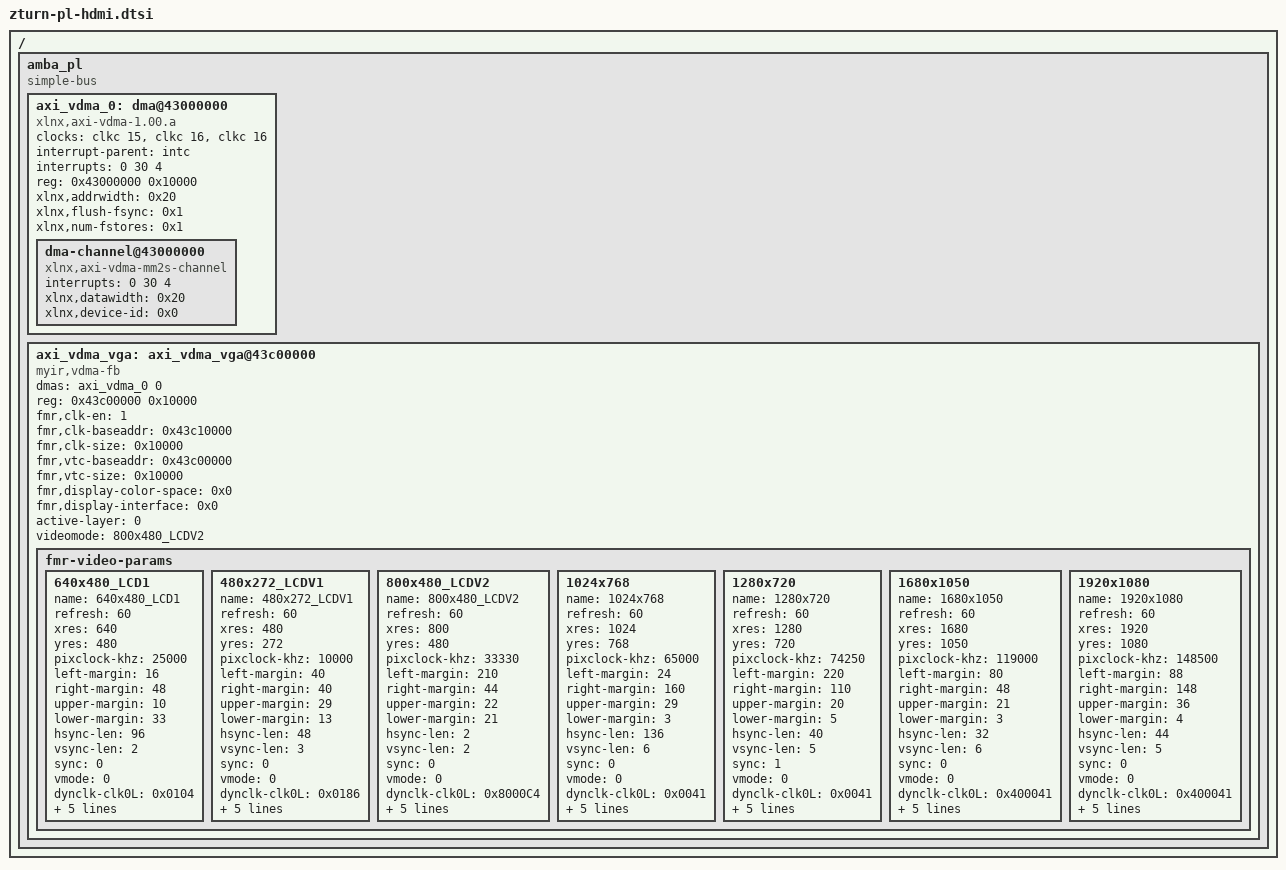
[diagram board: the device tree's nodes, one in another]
/*
 * CAUTION: This file is automatically generated by Xilinx.
 * Version:  
 * Today is: Tue Dec 25 14:02:03 2018
 */


/ {
	amba_pl: amba_pl {
		#address-cells = <1>;
		#size-cells = <1>;
		compatible = "simple-bus";
		ranges ;

		axi_vdma_0: dma@43000000 {
			#dma-cells = <1>;
			clock-names = "s_axi_lite_aclk", "m_axi_mm2s_aclk", "m_axi_mm2s_aclk";
			clocks = <&clkc 15>, <&clkc 16>, <&clkc 16>;
			compatible = "xlnx,axi-vdma-1.00.a";
			interrupt-names = "mm2s_introut";
			interrupt-parent = <&intc>;
			interrupts = <0 30 4>;
			reg = <0x43000000 0x10000>;
			xlnx,addrwidth = <0x20>;
			xlnx,flush-fsync = <0x1>;
			xlnx,num-fstores = <0x1>;
			dma-channel@43000000 {
				compatible = "xlnx,axi-vdma-mm2s-channel";
				interrupts = <0 30 4>;
				xlnx,datawidth = <0x20>;
				xlnx,device-id = <0x0>;
			};
		};

		axi_vdma_vga: axi_vdma_vga@43c00000 {
			compatible = "myir,vdma-fb";
			dmas = <&axi_vdma_0 0>;
			dma-names = "axivdma";
			reg = <0x43c00000 0x10000>;
			fmr,clk-en = <1>; // enable or disable dynclk
			fmr,clk-baseaddr = <0x43c10000>;
			fmr,clk-size = <0x10000>;
			fmr,vtc-baseaddr = <0x43c00000>; 
			fmr,vtc-size = <0x10000>; 
			fmr,display-color-space = <0x0>; 	//RGB
			fmr,display-interface = <0x0>;
			active-layer = <0>;
			videomode = "800x480_LCDV2";

			fmr-video-params {
				640x480_LCD1{
					name = "640x480_LCD1";
					refresh = <60>;
					xres = <640>;
					yres = <480>;
					pixclock-khz = <25000>;
					left-margin = <16>;
					right-margin = <48>;
					upper-margin = <10>;
					lower-margin = <33>;
					hsync-len = <96>;
					vsync-len = <2>;
					sync = <0>;
					vmode = <0>;

					dynclk-clk0L = <0x0104>;
					dynclk-clkFBL = <0x0145>;
					dynclk-clkFBH_clk0H = <0>;
					dynclk-divclk = <0x1041>;
					dynclk-lockL = <0x3E8FA401>;
					dynclk-fltr_lockH = <0x4B00E7>;
				};
				480x272_LCDV1{
					name = "480x272_LCDV1";
					refresh = <60>;
					xres = <480>;
					yres = <272>;
					pixclock-khz = <10000>;
					left-margin = <40>;
					right-margin = <40>;
					upper-margin = <29>;
					lower-margin = <13>;
					hsync-len = <48>;
					vsync-len = <3>;
					sync = <0>;
					vmode = <0>;

					dynclk-clk0L = <0x0186>;
					dynclk-clkFBL = <0x00C3>;
					dynclk-clkFBH_clk0H = <0>;
					dynclk-divclk = <0x1041>;
					dynclk-lockL = <0x7E8FA401>;
					dynclk-fltr_lockH = <0x73008C>;
				};
				800x480_LCDV2 {
					name = "800x480_LCDV2";
					refresh = <60>;
					xres = <800>;
					yres = <480>;
					pixclock-khz = <33330>;
					left-margin = <210>;
					right-margin = <44>;
					upper-margin = <22>;
					lower-margin = <21>;
					hsync-len = <2>;
					vsync-len = <2>;
					sync = <0>;
					vmode = <0>;

					dynclk-clk0L = <0x8000C4>;
					dynclk-clkFBL = <0x800452>;
					dynclk-clkFBH_clk0H = <0>;
					dynclk-divclk = <0x2042>;
					dynclk-lockL = <0xD13FA401>;
					dynclk-fltr_lockH = <0x6300FF>;
				};
				1024x768 {
					name = "1024x768";
					refresh = <60>;
					xres = <1024>;
					yres = <768>;
					pixclock-khz = <65000>;
					left-margin = <24>;//H Front Porch
					right-margin = <160>;//H Back Porch
					upper-margin = <29>;//V Back Porch
					lower-margin = <3>;//V Front Porch
					hsync-len = <136>;//H Sync Time
					vsync-len = <6>;//V Sync Time
					sync = <0>;
					vmode = <0>;

					dynclk-clk0L = <0x0041>;
					dynclk-clkFBL = <0x800187>;
					dynclk-clkFBH_clk0H = <0>;
					dynclk-divclk = <0x0041>;
					dynclk-lockL = <0xEEEFA401>;
					dynclk-fltr_lockH = <0xB300FF>;
				};
				1280x720 {
					name = "1280x720";
					refresh = <60>;
					xres = <1280>;
					yres = <720>;
					pixclock-khz = <74250>;
					left-margin = <220>;
					right-margin = <110>;
					upper-margin = <20>;
					lower-margin = <5>;
					hsync-len = <40>;
					vsync-len = <5>;
					sync = <1>;
					vmode = <0>;

					dynclk-clk0L = <0x0041>;
					dynclk-clkFBL = <0x069A>;
					dynclk-clkFBH_clk0H = <0>;
					dynclk-divclk = <0x20C4>;
					dynclk-lockL = <0xCFAFA401>;
					dynclk-fltr_lockH = <0xA300FF>;
				};
				1680x1050 {
					name = "1680x1050";
					refresh = <60>;
					xres = <1680>;
					yres = <1050>;
					pixclock-khz = <119000>;
					left-margin = <80>;
					right-margin = <48>;
					upper-margin = <21>;
					lower-margin = <3>;
					hsync-len = <32>;
					vsync-len = <6>;
					sync = <0>;
					vmode = <0>;

					dynclk-clk0L = <0x400041>;
					dynclk-clkFBL = <0x00C3>;
					dynclk-clkFBH_clk0H = <0>;
					dynclk-divclk = <0x1041>;
					dynclk-lockL = <0x7E8FA401>;
					dynclk-fltr_lockH = <0x73008C>;
				};
				1920x1080 {
					name = "1920x1080";
					refresh = <60>;
					xres = <1920>;
					yres = <1080>;
					pixclock-khz = <148500>;
					left-margin = <88>;	//H Front Porch
					right-margin = <148>;	//H Back Porch
					upper-margin = <36>;	//V Back Porch
					lower-margin = <4>;	//V Front Porch
					hsync-len = <44>;	//H Sync Time
					vsync-len = <5>;	//V Sync Time
					sync = <0>;
					vmode = <0>;

					dynclk-clk0L = <0x400041>;
					dynclk-clkFBL = <0x069A>;
					dynclk-clkFBH_clk0H = <0>;
					dynclk-divclk = <0x20C4>;
					dynclk-lockL = <0xCFAFA401>;
					dynclk-fltr_lockH = <0xA300FF>;
				};
			};
		};
	};
};
